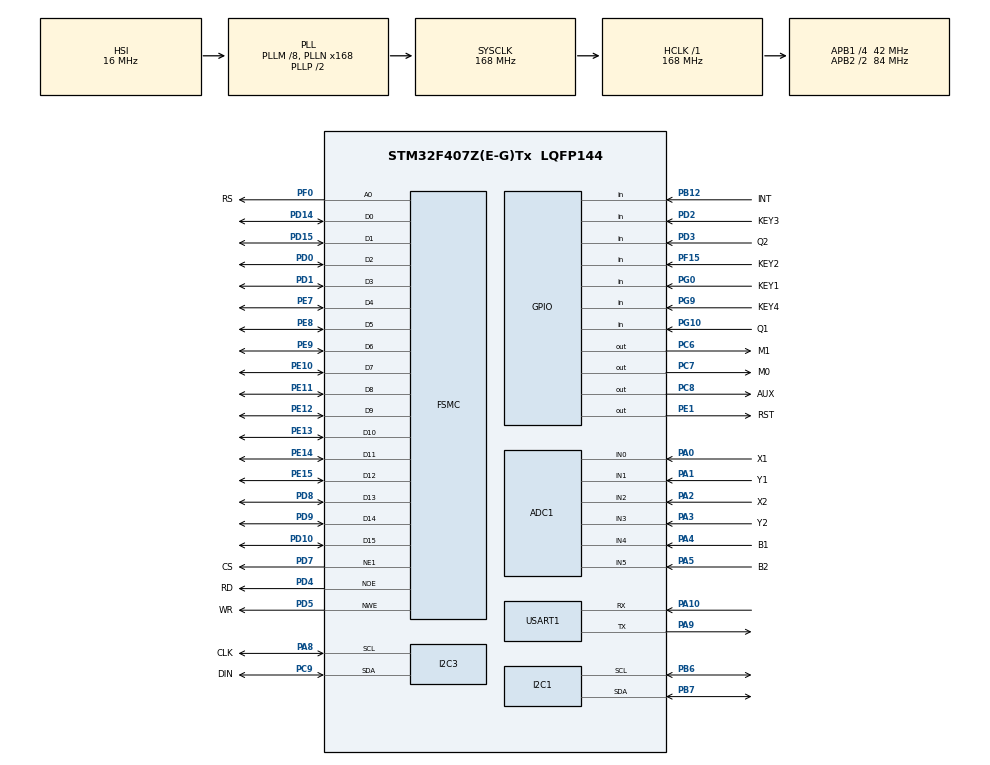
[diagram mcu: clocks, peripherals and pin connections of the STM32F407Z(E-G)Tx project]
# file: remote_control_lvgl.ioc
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ADC1.Channel-0\#ChannelRegularConversion=ADC_CHANNEL_0
ADC1.Channel-1\#ChannelRegularConversion=ADC_CHANNEL_1
ADC1.Channel-2\#ChannelRegularConversion=ADC_CHANNEL_2
ADC1.Channel-3\#ChannelRegularConversion=ADC_CHANNEL_3
ADC1.Channel-4\#ChannelRegularConversion=ADC_CHANNEL_4
ADC1.Channel-5\#ChannelRegularConversion=ADC_CHANNEL_5
ADC1.ContinuousConvMode=ENABLE
ADC1.DMAContinuousRequests=ENABLE
ADC1.InjNumberOfConversion=0
ADC1.NbrOfConversion=6
ADC1.NbrOfConversionFlag=1
ADC1.Rank-0\#ChannelRegularConversion=1
ADC1.Rank-1\#ChannelRegularConversion=2
ADC1.Rank-2\#ChannelRegularConversion=3
ADC1.Rank-3\#ChannelRegularConversion=4
ADC1.Rank-4\#ChannelRegularConversion=5
ADC1.Rank-5\#ChannelRegularConversion=6
ADC1.SamplingTime-0\#ChannelRegularConversion=ADC_SAMPLETIME_56CYCLES
ADC1.SamplingTime-1\#ChannelRegularConversion=ADC_SAMPLETIME_56CYCLES
ADC1.SamplingTime-2\#ChannelRegularConversion=ADC_SAMPLETIME_56CYCLES
ADC1.SamplingTime-3\#ChannelRegularConversion=ADC_SAMPLETIME_56CYCLES
ADC1.SamplingTime-4\#ChannelRegularConversion=ADC_SAMPLETIME_56CYCLES
ADC1.SamplingTime-5\#ChannelRegularConversion=ADC_SAMPLETIME_56CYCLES
ADC1.ScanConvMode=ENABLE
ADC1.master=1
Dma.ADC1.0.Direction=DMA_PERIPH_TO_MEMORY
Dma.ADC1.0.FIFOMode=DMA_FIFOMODE_DISABLE
Dma.ADC1.0.Instance=DMA2_Stream0
Dma.ADC1.0.MemDataAlignment=DMA_MDATAALIGN_HALFWORD
Dma.ADC1.0.MemInc=DMA_MINC_ENABLE
Dma.ADC1.0.Mode=DMA_CIRCULAR
Dma.ADC1.0.PeriphDataAlignment=DMA_PDATAALIGN_HALFWORD
Dma.ADC1.0.PeriphInc=DMA_PINC_DISABLE
Dma.ADC1.0.Priority=DMA_PRIORITY_LOW
Dma.Request0=ADC1
FREERTOS.Tasks01=ADC_TASK,0,128,ADC_Task,As weak,NULL,Dynamic,NULL,NULL;LVGL_TASK,0,2048,lvgl_task,As weak,NULL,Dynamic,NULL,NULL
FSMC.ExtendedMode1=FSMC_EXTENDED_MODE_DISABLE
FSMC.WriteOperation1=FSMC_WRITE_OPERATION_ENABLE
Mcu.Family=STM32F4
Mcu.Name=STM32F407Z(E-G)Tx
Mcu.Package=LQFP144
NVIC.DMA2_Stream0_IRQn=true\:5\:0\:false\:false\:true\:true\:false\:true\:true
NVIC.PriorityGroup=NVIC_PRIORITYGROUP_4
NVIC.TIM6_DAC_IRQn=true\:15\:0\:false\:false\:true\:false\:false\:true\:true
NVIC.TimeBase=TIM6_DAC_IRQn
NVIC.TimeBaseIP=TIM6
PA0-WKUP.GPIO_Label=X1
PA0-WKUP.Signal=ADCx_IN0
PA1.GPIO_Label=Y1
PA1.Signal=ADCx_IN1
PA10.Mode=Asynchronous
PA10.Signal=USART1_RX
PA13.Mode=Serial_Wire
PA13.Signal=SYS_JTMS-SWDIO
PA14.Mode=Serial_Wire
PA14.Signal=SYS_JTCK-SWCLK
PA2.GPIO_Label=X2
PA2.Signal=ADCx_IN2
PA3.GPIO_Label=Y2
PA3.Signal=ADCx_IN3
PA4.GPIO_Label=B1
PA4.Signal=ADCx_IN4
PA5.GPIO_Label=B2
PA5.Signal=ADCx_IN5
PA8.GPIO_Label=CLK
PA8.Mode=I2C
PA8.Signal=I2C3_SCL
PA9.Mode=Asynchronous
PA9.Signal=USART1_TX
PB12.GPIO_Label=INT
PB12.GPIO_PuPd=GPIO_PULLUP
PB12.Signal=GPIO_Input
PB6.Mode=I2C
PB6.Signal=I2C1_SCL
PB7.Mode=I2C
PB7.Signal=I2C1_SDA
PC6.GPIO_Label=M1
PC6.Signal=GPIO_Output
PC7.GPIO_Label=M0
PC7.Signal=GPIO_Output
PC8.GPIO_Label=AUX
PC8.Signal=GPIO_Output
PC9.GPIO_Label=DIN
PC9.Mode=I2C
PC9.Signal=I2C3_SDA
PD0.Signal=FSMC_D2_DA2
PD1.Signal=FSMC_D3_DA3
PD10.Signal=FSMC_D15_DA15
PD14.Signal=FSMC_D0_DA0
PD15.Signal=FSMC_D1_DA1
PD2.GPIO_Label=KEY3
PD2.Signal=GPIO_Input
PD3.GPIO_Label=Q2
PD3.Signal=GPIO_Input
PD4.GPIO_Label=RD
PD4.Signal=FSMC_NOE
PD5.GPIO_Label=WR
PD5.Signal=FSMC_NWE
PD7.GPIO_Label=CS
PD7.GPIO_PuPd=GPIO_PULLUP
PD7.Mode=NorPsramChipSelect1_1
PD7.Signal=FSMC_NE1
PD8.Signal=FSMC_D13_DA13
PD9.Signal=FSMC_D14_DA14
PE1.GPIO_Label=RST
PE1.GPIO_PuPd=GPIO_PULLUP
PE1.GPIO_Speed=GPIO_SPEED_FREQ_VERY_HIGH
PE1.Signal=GPIO_Output
PE10.Signal=FSMC_D7_DA7
PE11.Signal=FSMC_D8_DA8
PE12.Signal=FSMC_D9_DA9
PE13.Signal=FSMC_D10_DA10
PE14.Signal=FSMC_D11_DA11
PE15.Signal=FSMC_D12_DA12
PE7.Signal=FSMC_D4_DA4
PE8.Signal=FSMC_D5_DA5
PE9.Signal=FSMC_D6_DA6
PF0.GPIO_Label=RS
PF0.Signal=FSMC_A0
PF15.GPIO_Label=KEY2
PF15.Signal=GPIO_Input
PG0.GPIO_Label=KEY1
PG0.Signal=GPIO_Input
PG10.GPIO_Label=Q1
PG10.Signal=GPIO_Input
PG9.GPIO_Label=KEY4
PG9.Signal=GPIO_Input
PH0-OSC_IN.Mode=HSE-External-Oscillator
PH0-OSC_IN.Signal=RCC_OSC_IN
PH1-OSC_OUT.Mode=HSE-External-Oscillator
PH1-OSC_OUT.Signal=RCC_OSC_OUT
ProjectManager.HeapSize=0x200
ProjectManager.StackSize=0x400
ProjectManager.TargetToolchain=MDK-ARM V5.32
RCC.48MHZClocksFreq_Value=84000000
RCC.AHBFreq_Value=168000000
RCC.APB1CLKDivider=RCC_HCLK_DIV4
RCC.APB1Freq_Value=42000000
RCC.APB1TimFreq_Value=84000000
RCC.APB2CLKDivider=RCC_HCLK_DIV2
RCC.APB2Freq_Value=84000000
RCC.APB2TimFreq_Value=168000000
RCC.CortexFreq_Value=168000000
RCC.HCLKFreq_Value=168000000
RCC.HSE_VALUE=16000000
RCC.HSI_VALUE=16000000
RCC.LSE_VALUE=32768
RCC.PLLM=8
RCC.PLLN=168
RCC.SYSCLKFreq_VALUE=168000000
RCC.SYSCLKSource=RCC_SYSCLKSOURCE_PLLCLK
RCC.VCOOutputFreq_Value=336000000
SH.ADCx_IN0.0=ADC1_IN0,IN0
SH.ADCx_IN1.0=ADC1_IN1,IN1
SH.ADCx_IN2.0=ADC1_IN2,IN2
SH.ADCx_IN3.0=ADC1_IN3,IN3
SH.ADCx_IN4.0=ADC1_IN4,IN4
SH.ADCx_IN5.0=ADC1_IN5,IN5
SH.FSMC_A0.0=FSMC_A0,1b-a1
SH.FSMC_D0_DA0.0=FSMC_D0,16b-d1
SH.FSMC_D10_DA10.0=FSMC_D10,16b-d1
SH.FSMC_D11_DA11.0=FSMC_D11,16b-d1
SH.FSMC_D12_DA12.0=FSMC_D12,16b-d1
SH.FSMC_D13_DA13.0=FSMC_D13,16b-d1
SH.FSMC_D14_DA14.0=FSMC_D14,16b-d1
SH.FSMC_D15_DA15.0=FSMC_D15,16b-d1
SH.FSMC_D1_DA1.0=FSMC_D1,16b-d1
SH.FSMC_D2_DA2.0=FSMC_D2,16b-d1
SH.FSMC_D3_DA3.0=FSMC_D3,16b-d1
SH.FSMC_D4_DA4.0=FSMC_D4,16b-d1
SH.FSMC_D5_DA5.0=FSMC_D5,16b-d1
SH.FSMC_D6_DA6.0=FSMC_D6,16b-d1
SH.FSMC_D7_DA7.0=FSMC_D7,16b-d1
SH.FSMC_D8_DA8.0=FSMC_D8,16b-d1
SH.FSMC_D9_DA9.0=FSMC_D9,16b-d1
SH.FSMC_NOE.0=FSMC_NOE,Sram1
SH.FSMC_NWE.0=FSMC_NWE,Sram1
USART1.VirtualMode=VM_ASYNC
VP_FREERTOS_VS_CMSIS_V1.Mode=CMSIS_V1
VP_SYS_VS_tim6.Mode=TIM6
board=custom

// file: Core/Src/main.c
/* USER CODE BEGIN Header */
/**
 ******************************************************************************
 * @file           : main.c
 * @brief          : Main program body
 ******************************************************************************
 * @attention
 *
 * Copyright (c) 2026 STMicroelectronics.
 * All rights reserved.
 *
 * This software is licensed under terms that can be found in the LICENSE file
 * in the root directory of this software component.
 * If no LICENSE file comes with this software, it is provided AS-IS.
 *
 ******************************************************************************
 */
/* USER CODE END Header */
#include "main.h"
#include "cmsis_os.h"
#include "adc.h"
#include "dma.h"
#include "i2c.h"
#include "usart.h"
#include "gpio.h"
#include "fsmc.h"

void SystemClock_Config(void);
void MX_FREERTOS_Init(void);

int main(void)
{

  /* MCU Configuration--------------------------------------------------------*/

  /* Reset of all peripherals, Initializes the Flash interface and the Systick. */
  HAL_Init();

  /* Configure the system clock */
  SystemClock_Config();

  /* Initialize all configured peripherals */
  MX_GPIO_Init();
  MX_DMA_Init();
  MX_ADC1_Init();
  MX_I2C3_Init();
  MX_USART1_UART_Init();
  MX_FSMC_Init();
  MX_I2C1_Init();

  /* Call init function for freertos objects (in cmsis_os2.c) */
  MX_FREERTOS_Init();

  /* Start scheduler */
  osKernelStart();

  /* We should never get here as control is now taken by the scheduler */

  /* Infinite loop */
  while (1)
  {

  }
}

void SystemClock_Config(void)
{
  RCC_OscInitTypeDef RCC_OscInitStruct = {0};
  RCC_ClkInitTypeDef RCC_ClkInitStruct = {0};

  /** Configure the main internal regulator output voltage
  */
  __HAL_RCC_PWR_CLK_ENABLE();
  __HAL_PWR_VOLTAGESCALING_CONFIG(PWR_REGULATOR_VOLTAGE_SCALE1);

  /** Initializes the RCC Oscillators according to the specified parameters
  * in the RCC_OscInitTypeDef structure.
  */
  RCC_OscInitStruct.OscillatorType = RCC_OSCILLATORTYPE_HSI;
  RCC_OscInitStruct.HSIState = RCC_HSI_ON;
  RCC_OscInitStruct.HSICalibrationValue = RCC_HSICALIBRATION_DEFAULT;
  RCC_OscInitStruct.PLL.PLLState = RCC_PLL_ON;
  RCC_OscInitStruct.PLL.PLLSource = RCC_PLLSOURCE_HSI;
  RCC_OscInitStruct.PLL.PLLM = 8;
  RCC_OscInitStruct.PLL.PLLN = 168;
  RCC_OscInitStruct.PLL.PLLP = RCC_PLLP_DIV2;
  RCC_OscInitStruct.PLL.PLLQ = 4;
  if (HAL_RCC_OscConfig(&RCC_OscInitStruct) != HAL_OK)
  {
    Error_Handler();
  }

  /** Initializes the CPU, AHB and APB buses clocks
  */
  RCC_ClkInitStruct.ClockType = RCC_CLOCKTYPE_HCLK|RCC_CLOCKTYPE_SYSCLK
                              |RCC_CLOCKTYPE_PCLK1|RCC_CLOCKTYPE_PCLK2;
  RCC_ClkInitStruct.SYSCLKSource = RCC_SYSCLKSOURCE_PLLCLK;
  RCC_ClkInitStruct.AHBCLKDivider = RCC_SYSCLK_DIV1;
  RCC_ClkInitStruct.APB1CLKDivider = RCC_HCLK_DIV4;
  RCC_ClkInitStruct.APB2CLKDivider = RCC_HCLK_DIV2;

  if (HAL_RCC_ClockConfig(&RCC_ClkInitStruct, FLASH_LATENCY_5) != HAL_OK)
  {
    Error_Handler();
  }
}

void HAL_TIM_PeriodElapsedCallback(TIM_HandleTypeDef *htim)
{
  if (htim->Instance == TIM6)
  {
    HAL_IncTick();
  }
}

void Error_Handler(void)
{
  __disable_irq();
  while (1)
  {
  }
}

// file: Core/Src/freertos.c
/* USER CODE BEGIN Header */
/**
  ******************************************************************************
  * File Name          : freertos.c
  * Description        : Code for freertos applications
  ******************************************************************************
  * @attention
  *
  * Copyright (c) 2026 STMicroelectronics.
  * All rights reserved.
  *
  * This software is licensed under terms that can be found in the LICENSE file
  * in the root directory of this software component.
  * If no LICENSE file comes with this software, it is provided AS-IS.
  *
  ******************************************************************************
  */
/* USER CODE END Header */

#include "FreeRTOS.h"
#include "task.h"
#include "main.h"
#include "cmsis_os.h"

/* USER CODE BEGIN Variables */
volatile uint32_t FreeRTOS_StackOverflowHit = 0;
volatile uint32_t FreeRTOS_StackOverflowTask = 0;
volatile char FreeRTOS_StackOverflowTaskName[16];

/* USER CODE END Variables */
osThreadId ADC_TASKHandle;
osThreadId LVGL_TASKHandle;

void ADC_Task(void const * argument);
void lvgl_task(void const * argument);

void MX_FREERTOS_Init(void); /* (MISRA C 2004 rule 8.1) */

/* GetIdleTaskMemory prototype (linked to static allocation support) */
void vApplicationGetIdleTaskMemory( StaticTask_t **ppxIdleTaskTCBBuffer, StackType_t **ppxIdleTaskStackBuffer, uint32_t *pulIdleTaskStackSize );

/* USER CODE BEGIN GET_IDLE_TASK_MEMORY */
static StaticTask_t xIdleTaskTCBBuffer;
static StackType_t xIdleStack[configMINIMAL_STACK_SIZE];

void vApplicationGetIdleTaskMemory( StaticTask_t **ppxIdleTaskTCBBuffer, StackType_t **ppxIdleTaskStackBuffer, uint32_t *pulIdleTaskStackSize )
{
  *ppxIdleTaskTCBBuffer = &xIdleTaskTCBBuffer;
  *ppxIdleTaskStackBuffer = &xIdleStack[0];
  *pulIdleTaskStackSize = configMINIMAL_STACK_SIZE;
  /* place for user code */
}
/* USER CODE END GET_IDLE_TASK_MEMORY */

void MX_FREERTOS_Init(void) {

  /* Create the thread(s) */
  /* definition and creation of ADC_TASK */
  osThreadDef(ADC_TASK, ADC_Task, osPriorityNormal, 0, 128);
  ADC_TASKHandle = osThreadCreate(osThread(ADC_TASK), NULL);

  /* definition and creation of LVGL_TASK */
  osThreadDef(LVGL_TASK, lvgl_task, osPriorityNormal, 0, 4096);
  LVGL_TASKHandle = osThreadCreate(osThread(LVGL_TASK), NULL);

}

__weak void ADC_Task(void const * argument)
{
  for(;;)
  {
    osDelay(1);
  }
}

__weak void lvgl_task(void const * argument)
{
  for(;;)
  {
    osDelay(1);
  }
}

/* USER CODE BEGIN Application */
void vApplicationStackOverflowHook(TaskHandle_t xTask, char *pcTaskName)
{
  uint32_t i;

  FreeRTOS_StackOverflowHit = 1;
  FreeRTOS_StackOverflowTask = (uint32_t)xTask;

  for(i = 0; i < (sizeof(FreeRTOS_StackOverflowTaskName) - 1U); i++) {
    if(pcTaskName == NULL || pcTaskName[i] == '\0') {
      break;
    }
    FreeRTOS_StackOverflowTaskName[i] = pcTaskName[i];
  }
  FreeRTOS_StackOverflowTaskName[i] = '\0';

  taskDISABLE_INTERRUPTS();
  while(1) {
  }
}

/* USER CODE END Application */
